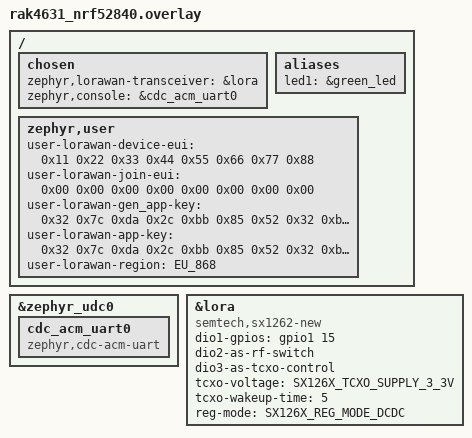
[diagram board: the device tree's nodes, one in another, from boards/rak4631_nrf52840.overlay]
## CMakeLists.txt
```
# SPDX-License-Identifier: Apache-2.0

cmake_minimum_required(VERSION 3.28.0)

find_package(Zephyr REQUIRED HINTS $ENV{ZEPHYR_BASE})
project(rzi_app)

target_sources(app PRIVATE src/main.c src/board.c)
target_link_libraries(app PRIVATE lbm_compile_definitions)
```

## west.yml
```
# 本文件是 west 清单（manifest）。west init / west update 只认根键 manifest:。
# 初始化：在工作区根 rzi/ 执行  west init -l app
#   -l = local，用本地这个 app/ 当老板仓，不去 GitHub 再 clone 一份清单仓。
# 不要给下面的 usp_zephyr 写 import: true，否则会并入它自带 west.yml 里锁死的 Zephyr v4.2.0。

# west 清单的唯一根键。self / remotes / projects 都必须缩进挂在它下面。
manifest:

  # 清单仓库自己（包含本 west.yml 的那个目录）。不是第三方，所以不进 projects，不会被 clone。
  self:
    # 老板仓相对工作区根的路径 → rzi/app。与 west init -l app、.west/config 里 path = app 一致。
    path: app

  # 远程 git 主机表。projects 里用 remote: 引用这里的 name，避免每个项目写完整 URL。
  remotes:
    # 列表第一项（- 表示一项）。名字 zephyrproject-rtos，下面 remote: zephyrproject-rtos 就是指它。
    - name: zephyrproject-rtos
      # URL 前缀。拼法：url-base + "/" + 项目 name → https://github.com/zephyrproject-rtos/zephyr
      url-base: https://github.com/zephyrproject-rtos
    # 第二个远程，给 Semtech 的 usp_zephyr 和 usp 用。
    - name: lora-net
      # LoRa-net 组织前缀。拼出 https://github.com/Lora-net/usp_zephyr 和 .../usp
      url-base: https://github.com/Lora-net

  # 要拉进工作区的第三方仓（不含 self）。west update 主要读这一块。
  projects:

    # 第一个项目。name 默认既是 GitHub 仓库名，也是本地目录名 → clone 到 rzi/zephyr/
    - name: zephyr
      # 用上面 remotes 里那个 zephyrproject-rtos → https://github.com/zephyrproject-rtos/zephyr
      remote: zephyrproject-rtos
      # 检出这一次 commit（当时的 Zephyr 4.4.99），不是浮动分支，也不是官方 USP 清单的 v4.2.0。
      revision: 161f758ba363ec90cd9b727a5d82e6c86efa85ad
      # 拉完后再读 zephyr/west.yml，把它列出的 HAL、mcuboot、tools 等并进本工作区。没有这行编 rak4631 会缺模块。
      import: true

    # 第二个项目。Semtech 的 Zephyr 封装（驱动、盾、sample、CMake）。clone 地址 = lora-net url-base + /usp_zephyr
    - name: usp_zephyr
      # → https://github.com/Lora-net/usp_zephyr
      remote: lora-net
      # 跟 main 分支最新提交。每次 west update 可能往前走；和上面 zephyr 钉 SHA 不同。
      revision: main
      # 放到工作区根下的 usp_zephyr/。这里 path 和 name 相同，不写也一样。
      # 注意：这一项没有 import: true，磁盘上的 usp_zephyr/west.yml west 不会读。
      # 本地改动用官方 west patch：app/zephyr/patches.yml，见 doc/west-patch.md。
      path: usp_zephyr

    # 第三个项目。协议栈本体（LBM + RAC），不是 usp_zephyr 那层封装。clone 地址 = https://github.com/Lora-net/usp
    - name: usp
      # 同样用 LoRa-net。
      remote: lora-net
      # 跟 usp 的 main，和 usp_zephyr 一样不锁死 SHA。
      revision: main
      # 本地必须放这里。这是 Zephyr/CMake 找 USP 模块的约定路径；放到别处构建系统找不到。
      path: modules/lib/usp
      # git clone / west update 时连该仓声明的 git submodule 一起拉（无线电驱动等）。不拉会缺源码。
      submodules: true
```

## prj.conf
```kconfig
# Own USP + LBM LoRaWAN app (not Zephyr CONFIG_LORAWAN / loramac-node).

# --- 板级外设 ---
CONFIG_BOARD_EARLY_INIT_HOOK=y         # app/src/board.c：全擦后把 REGOUT0 写成 3.3 V
CONFIG_GPIO=y                          # LED、SX1262 DIO / reset / busy
CONFIG_SPI=y                           # 和 SX1262 通信
CONFIG_SERIAL=y                        # UART 子系统（本板实际走 USB CDC）

# --- 控制台（overlay: zephyr,console = cdc_acm_uart0） ---
CONFIG_CONSOLE=y
CONFIG_UART_CONSOLE=y                  # printk / LOG 走 UART console
CONFIG_UART_LINE_CTRL=y                # CDC DTR；main.c wait_usb_console() 等主机打开串口
CONFIG_USE_SEGGER_RTT=n                # 关掉 RTT，日志不要跑到 J-Link

# --- USB CDC ACM：插 USB 当虚拟串口看 log ---
CONFIG_USB_DEVICE_STACK_NEXT=y         # 新 USB device 栈
CONFIG_CDC_ACM_SERIAL_INITIALIZE_AT_BOOT=y
CONFIG_CDC_ACM_SERIAL_PRODUCT_STRING="RAK4631 USP"
# 等 USB 枚举完再刷 log，避免开机丢字。数字赋值不要写同行注释。
CONFIG_LOG_PROCESS_THREAD_STARTUP_DELAY_MS=4000
CONFIG_USBD_CDC_ACM_LOG_LEVEL_OFF=y    # USB 栈自己的 log 关掉，枚举时不刷屏
CONFIG_USBD_LOG_LEVEL_OFF=y

# --- 日志与内存 ---
CONFIG_LOG=y
CONFIG_LOG_BACKEND_SHOW_COLOR=n        # CDC 不是彩色终端
CONFIG_LOG_BUFFER_SIZE=4096
CONFIG_HEAP_MEM_POOL_SIZE=8192
CONFIG_MAIN_STACK_SIZE=4096

# --- 存储 / 电源 / 随机数 ---
CONFIG_FLASH=y                         # LBM 把 Join 会话写 NVM
CONFIG_PM_DEVICE=y                     # 设备级电源管理（电台驱动会用）
CONFIG_TEST_RANDOM_GENERATOR=y         # 软件伪随机；Join DevNonce 等需要

# --- 关掉 Zephyr 自带 LoRa/LoRaWAN，避免和 USP 抢同一颗 SX1262 ---
CONFIG_LORA=n
CONFIG_LORAWAN=n

# --- USP + LoRa Basics Modem ---
CONFIG_LORA_BASICS_MODEM_DRIVERS=y     # SX1262 走 USP 驱动，不是树上 semtech,sx1262
CONFIG_LORA_BASICS_MODEM_DRIVERS_EVENT_TRIGGER_NO_THREAD=y  # DIO IRQ 不经中间线程，时间戳更准
CONFIG_USP=y
CONFIG_USP_LORA_BASICS_MODEM=y         # 编进 LBM 协议栈（join / MAC / 区域）
CONFIG_USP_MAIN_THREAD=y               # USP 自己跑 RAC 线程；main 只 init 然后 k_sleep

# --- 线程优先级（负数 = 协作式，不抢占；数字越小优先级越高） ---
# USP(-4) > main(-2)：main 让出 CPU 后 USP 立刻跑，临界区简单
CONFIG_MAIN_THREAD_PRIORITY=-2
CONFIG_USP_MAIN_THREAD_PRIORITY=-4
```

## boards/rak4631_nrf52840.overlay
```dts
/*
 * RAK4631：把板上 SX1262 交给 usp_zephyr，不要用树上的 Zephyr LoRa 驱动。
 *
 * 板级 dts 已有 &lora（SPI、reset、busy）和 aliases { lora0 }。
 * 树上 compatible 是 "semtech,sx1262"；本 overlay 改成 "semtech,sx1262-new"。
 *
 * 入网前改 zephyr,user 里的密钥。
 */

/* USP 头：SX126X_TCXO_SUPPLY_*、SX126X_REG_MODE_*。不是 Zephyr 自带的。 */
#include <zephyr/dt-bindings/usp/sx126x.h>

/ {
	chosen {
		/* USP：线程 / HAL 用 DT_CHOSEN(zephyr_lorawan_transceiver) 找电台 */
		zephyr,lorawan-transceiver = &lora;

		/* 日志走 USB CDC，与 USP 无关。板级默认是 uart1 */
		zephyr,console = &cdc_acm_uart0;
	};

	aliases {
		/* 板级只有 led0=蓝灯；绿灯给 main.c DT_ALIAS(led1) */
		led1 = &green_led;
	};

	/*
	 * 节点名 zephyr,user 是 Zephyr 通用的。
	 * 下面 user-lorawan-* 是 USP LBM sample / 本 app main.c 的约定。
	 */
	zephyr,user {
		/* ChirpStack 设备 RZI_001 */
		user-lorawan-device-eui = <0x11 0x22 0x33 0x44 0x55 0x66 0x77 0x88>;
		/* Configuration 页若不是全 0，改成和 Join EUI 一致 */
		user-lorawan-join-eui = <0x00 0x00 0x00 0x00 0x00 0x00 0x00 0x00>;
		/* Gen App Key（Remote Multicast）；LBM set_appkey */
		user-lorawan-gen_app-key = <0x32 0x7c 0xda 0x2c 0xbb 0x85 0x52 0x32
					    0xbe 0x7a 0x08 0xf5 0xc7 0x92 0xec 0x58>;
		/* OTAA AppKey；LoRaWAN 1.0 里 LBM set_nwkkey */
		user-lorawan-app-key = <0x32 0x7c 0xda 0x2c 0xbb 0x85 0x52 0x32
					0xbe 0x7a 0x08 0xf5 0xc7 0x92 0xec 0x58>;
		/* EU_868, CN_470, AS_923_GRP1, US_915, ... */
		user-lorawan-region = "EU_868";
	};
};

/* 普通 Zephyr USB CDC，与 USP 无关 */
&zephyr_udc0 {
	cdc_acm_uart0: cdc_acm_uart0 {
		compatible = "zephyr,cdc-acm-uart";
	};
};

/* USP 电台节点：binding 见 usp_zephyr/dts/bindings/usp/semtech,sx126x-new-common.yaml */
&lora {
	compatible = "semtech,sx1262-new";
	/* 脚位与板级 dts 相同；PULL_DOWN 给 USP 驱动 */
	dio1-gpios = <&gpio1 15 (GPIO_ACTIVE_HIGH | GPIO_PULL_DOWN)>;
	/* 以下属性只存在于 sx126x-new，树上旧驱动没有 */
	dio2-as-rf-switch;
	dio3-as-tcxo-control;
	/* 与 beegee SX126x-Arduino hw_config.TCXO_CTRL_VOLTAGE 默认值一致 */
	tcxo-voltage = <SX126X_TCXO_SUPPLY_3_3V>;
	tcxo-wakeup-time = <5>;
	reg-mode = <SX126X_REG_MODE_DCDC>;
	/* 删掉树上 semtech,sx1262 的旧属性，避免和新 binding 冲突 */
	/delete-property/ dio2-tx-enable;
	/delete-property/ dio3-tcxo-voltage;
	/delete-property/ tcxo-power-startup-delay-ms;
	/delete-property/ rx-enable-gpios;
};
```

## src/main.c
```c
/*
 * RAK4631 + usp_zephyr LoRaWAN example (app/, not usp_zephyr/samples).
 * OTAA join, then a 4-byte confirmed counter every 5 s on port 1.
 *
 * Fill DevEUI / JoinEUI / keys / region in boards/rak4631_nrf52840.overlay.
 */

#include <zephyr/kernel.h>
#include <zephyr/devicetree.h>
#include <zephyr/logging/log.h>
#include <zephyr/drivers/gpio.h>
#include <zephyr/drivers/uart.h>
#include <hal/nrf_power.h>

#include <smtc_modem_api.h>
#include <smtc_modem_utilities.h>
#include <smtc_zephyr_usp_api.h>
#include <smtc_sw_platform_helper.h>

LOG_MODULE_REGISTER(usp, LOG_LEVEL_INF);

#define STACK_ID 0
#define PERIOD_S 5
#define UPLINK_PORT 1

#define DT_MODEM_REGION(region) DT_CAT(SMTC_MODEM_REGION_, region)
#define MODEM_REGION DT_MODEM_REGION(DT_STRING_UNQUOTED(DT_PATH(zephyr_user), user_lorawan_region))

static const uint8_t user_dev_eui[8] = DT_PROP(DT_PATH(zephyr_user), user_lorawan_device_eui);
static const uint8_t user_join_eui[8] = DT_PROP(DT_PATH(zephyr_user), user_lorawan_join_eui);
static const uint8_t user_gen_app_key[16] = DT_PROP(DT_PATH(zephyr_user), user_lorawan_gen_app_key);
static const uint8_t user_app_key[16] = DT_PROP(DT_PATH(zephyr_user), user_lorawan_app_key);

static const struct gpio_dt_spec led_blue = GPIO_DT_SPEC_GET(DT_ALIAS(led0), gpios);
static const struct gpio_dt_spec led_green = GPIO_DT_SPEC_GET(DT_ALIAS(led1), gpios);

/* P1.05 = Arduino 37。Bernd：RADIO_RXEN + USE_RXEN_ANT_PWR = 天线开关的供电脚，
 * 不是通路选择脚。高电平有效，通电后方向由 SX1262 的 DIO2 自己切换，
 * 所以这里只需要常开、不需要每次 TX/RX 反复动作。 */
#define ANT_SWITCH_PWR_PIN 5
/* P1.07 原理图接到开关控制，官方要求不要初始化，交给 DIO2。 */
#define ANT_SWITCH_CTRL_PIN 7

static uint32_t uplink_counter;

static void led_set(const struct gpio_dt_spec *led, int value)
{
	if (gpio_is_ready_dt(led)) {
		gpio_pin_set_dt(led, value);
	}
}

static void led_green_blink_handler(struct k_timer *timer)
{
	ARG_UNUSED(timer);
	if (gpio_is_ready_dt(&led_green)) {
		gpio_pin_toggle_dt(&led_green);
	}
}

static void led_blue_off_work_handler(struct k_work *work)
{
	ARG_UNUSED(work);
	led_set(&led_blue, 0);
}

static K_TIMER_DEFINE(led_green_blink, led_green_blink_handler, NULL);
static K_WORK_DELAYABLE_DEFINE(led_blue_off_work, led_blue_off_work_handler);

static void led_blue_off(void)
{
	(void)k_work_cancel_delayable(&led_blue_off_work);
	led_set(&led_blue, 0);
}

/* 入网前绿灯闪；入网后绿灯常亮。蓝灯常灭，只在发送时快闪。 */
static void leds_joining(void)
{
	led_blue_off();
	led_set(&led_green, 1);
	k_timer_start(&led_green_blink, K_MSEC(500), K_MSEC(500));
}

static void leds_joined(void)
{
	k_timer_stop(&led_green_blink);
	led_set(&led_green, 1);
	led_blue_off();
}

/* 蓝灯常灭；每次上行快闪一下。关灯走 workqueue，避免 timer ISR 里 GPIO 没落下去。 */
static void led_blue_flash(void)
{
	led_set(&led_blue, 1);
	(void)k_work_reschedule(&led_blue_off_work, K_MSEC(80));
}

static int leds_init(void)
{
	if (!gpio_is_ready_dt(&led_blue) || !gpio_is_ready_dt(&led_green)) {
		LOG_ERR("LED gpio not ready");
		return -ENODEV;
	}

	gpio_pin_configure_dt(&led_blue, GPIO_OUTPUT_INACTIVE);
	gpio_pin_configure_dt(&led_green, GPIO_OUTPUT_INACTIVE);
	led_blue_off();
	return 0;
}

static void antenna_switch_power_on(void)
{
	const struct device *gpio1 = DEVICE_DT_GET(DT_NODELABEL(gpio1));
	int p105;

	if (!device_is_ready(gpio1)) {
		LOG_ERR("gpio1 not ready, P1.05 not driven");
		return;
	}

	/* 不要驱动 P1.07，避免和 SX1262 DIO2 抢开关。 */
	gpio_pin_configure(gpio1, ANT_SWITCH_CTRL_PIN, GPIO_INPUT);

	/*
	 * P1.05 是 RF 天线开关的供电（SX126x-Arduino USE_RXEN_ANT_PWR）。
	 * Bernd lora_rak4630_init：TX/RX 都 digitalWrite(37, HIGH)。
	 * 高电平才打开通路；板上 dts 的 GPIO_ACTIVE_LOW 是错的，别照抄。
	 */
	gpio_pin_configure(gpio1, ANT_SWITCH_PWR_PIN, GPIO_OUTPUT_HIGH);

	p105 = gpio_pin_get_raw(gpio1, ANT_SWITCH_PWR_PIN);
	LOG_INF("P1.05 raw=%d (expect 1) REGOUT0=0x%08x (3V3=5)", p105,
		(uint32_t)(NRF_UICR->REGOUT0 & UICR_REGOUT0_VOUT_Msk) >> UICR_REGOUT0_VOUT_Pos);
}

static void check_rc(const char *what, smtc_modem_return_code_t rc)
{
	if (rc != SMTC_MODEM_RC_OK) {
		LOG_ERR("%s failed: %d", what, rc);
	}
}

static void send_counter(void)
{
	uint8_t buff[4] = {
		(uplink_counter >> 24) & 0xFF,
		(uplink_counter >> 16) & 0xFF,
		(uplink_counter >> 8) & 0xFF,
		uplink_counter & 0xFF,
	};

	/* 天线开关供电是常开的（见 antenna_switch_power_on），这里不再重配
	 * 引脚：每次 uplink 前 gpio_pin_configure 会让脚短暂脱离输出态，
	 * 反而可能在 TX 瞬间把开关断电。 */
	smtc_modem_return_code_t rc =
		smtc_modem_request_uplink(STACK_ID, UPLINK_PORT, true, buff, sizeof(buff));
	if (rc != SMTC_MODEM_RC_OK) {
		LOG_ERR("uplink failed: %d", rc);
		return;
	}
	led_blue_flash();
	LOG_INF("confirmed uplink #%u on port %u", uplink_counter, UPLINK_PORT);
	uplink_counter++;
}

static void modem_event_callback(void)
{
	smtc_modem_event_t event = {0};
	uint8_t pending;

	do {
		check_rc("get_event", smtc_modem_get_event(&event, &pending));

		switch (event.event_type) {
		case SMTC_MODEM_EVENT_RESET:
			LOG_INF("RESET: set keys, region, join");
			leds_joining();
			check_rc("set_deveui", smtc_modem_set_deveui(STACK_ID, user_dev_eui));
			check_rc("set_joineui", smtc_modem_set_joineui(STACK_ID, user_join_eui));
			check_rc("set_appkey", smtc_modem_set_appkey(STACK_ID, user_gen_app_key));
			check_rc("set_nwkkey", smtc_modem_set_nwkkey(STACK_ID, user_app_key));
			check_rc("set_region", smtc_modem_set_region(STACK_ID, MODEM_REGION));
			/* 关掉 LoRaWAN Join 占空比退避（首小时约 toa/10，SF10 大约几十秒一次）。
			 * 调试用；量产应关掉，按规范退避。 */
			check_rc("join_dc_bypass",
				 smtc_modem_set_join_duty_cycle_backoff_bypass(STACK_ID, true));
			antenna_switch_power_on();
			check_rc("join", smtc_modem_join_network(STACK_ID));
			break;

		case SMTC_MODEM_EVENT_JOINED:
			LOG_INF("JOINED");
			leds_joined();
			send_counter();
			check_rc("alarm", smtc_modem_alarm_start_timer(PERIOD_S));
			break;

		case SMTC_MODEM_EVENT_JOINFAIL:
			LOG_WRN("JOINFAIL, retry in %u s", PERIOD_S);
			leds_joining();
			/* 取消 LBM 自己的 join 退避，改由 alarm 每 5 s 再 join */
			(void)smtc_modem_leave_network(STACK_ID);
			check_rc("alarm", smtc_modem_alarm_start_timer(PERIOD_S));
			break;

		case SMTC_MODEM_EVENT_ALARM: {
			smtc_modem_status_mask_t status = 0;

			check_rc("get_status", smtc_modem_get_status(STACK_ID, &status));
			if ((status & SMTC_MODEM_STATUS_JOINED) != 0) {
				send_counter();
				check_rc("alarm", smtc_modem_alarm_start_timer(PERIOD_S));
			} else {
				LOG_INF("join retry");
				check_rc("join", smtc_modem_join_network(STACK_ID));
			}
			break;
		}

		case SMTC_MODEM_EVENT_TXDONE: {
			smtc_modem_event_txdone_status_t st = event.event_data.txdone.status;

			if (st == SMTC_MODEM_EVENT_TXDONE_CONFIRMED) {
				LOG_INF("TXDONE ACK");
			} else if (st == SMTC_MODEM_EVENT_TXDONE_SENT) {
				LOG_WRN("TXDONE sent, no ACK");
			} else {
				LOG_WRN("TXDONE not sent (%d)", st);
			}
			led_blue_off();
			break;
		}

		case SMTC_MODEM_EVENT_DOWNDATA: {
			uint8_t payload[SMTC_MODEM_MAX_LORAWAN_PAYLOAD_LENGTH];
			uint8_t size = 0;
			uint8_t remaining = 0;
			smtc_modem_dl_metadata_t meta = {0};

			check_rc("downlink",
				 smtc_modem_get_downlink_data(payload, &size, &meta, &remaining));
			LOG_INF("DOWNLINK port %u, %u bytes", meta.fport, size);
			break;
		}

		default:
			LOG_DBG("event %u", event.event_type);
			break;
		}
	} while (pending > 0);
}

static void wait_usb_console(void)
{
	const struct device *dev = DEVICE_DT_GET(DT_CHOSEN(zephyr_console));
	uint32_t dtr = 0;
	int64_t deadline = k_uptime_get() + 10000;

	if (!device_is_ready(dev)) {
		return;
	}

	while (dtr == 0 && k_uptime_get() < deadline) {
		(void)uart_line_ctrl_get(dev, UART_LINE_CTRL_DTR, &dtr);
		k_sleep(K_MSEC(100));
	}
}

int main(void)
{
	(void)leds_init();
	leds_joining();

	wait_usb_console();

	LOG_INF("rzi USP LoRaWAN on %s", CONFIG_BOARD_TARGET);
	LOG_INF("DevEUI %02X%02X%02X%02X%02X%02X%02X%02X", user_dev_eui[0], user_dev_eui[1],
		user_dev_eui[2], user_dev_eui[3], user_dev_eui[4], user_dev_eui[5], user_dev_eui[6],
		user_dev_eui[7]);

	antenna_switch_power_on();

	SMTC_SW_PLATFORM_INIT();
	SMTC_SW_PLATFORM_VOID(smtc_rac_init());
	SMTC_SW_PLATFORM_VOID(smtc_modem_init(&modem_event_callback));

	LOG_INF("joining (edit keys in boards/rak4631_nrf52840.overlay)");

	k_sleep(K_FOREVER);
	return 0;
}
```

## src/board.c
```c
/*
 * RAK4631: nRF52840 runs from VDDH. After a full erase, UICR REGOUT0
 * defaults to 1.8 V. LEDs/USB may still work, but SX1262 GPIOs do not.
 * Write REGOUT0 to 3.3 V and reset so the new GPIO voltage takes effect.
 *
 * Official rak4631 board has no board.c; keep this in the app so west
 * update does not wipe it.
 */

#include <zephyr/init.h>
#include <hal/nrf_power.h>

void board_early_init_hook(void)
{
	if ((nrf_power_mainregstatus_get(NRF_POWER) == NRF_POWER_MAINREGSTATUS_HIGH) &&
	    ((NRF_UICR->REGOUT0 & UICR_REGOUT0_VOUT_Msk) ==
	     (UICR_REGOUT0_VOUT_DEFAULT << UICR_REGOUT0_VOUT_Pos))) {

		NRF_NVMC->CONFIG = NVMC_CONFIG_WEN_Wen << NVMC_CONFIG_WEN_Pos;
		while (NRF_NVMC->READY == NVMC_READY_READY_Busy) {
			;
		}

		NRF_UICR->REGOUT0 =
			(NRF_UICR->REGOUT0 & ~((uint32_t)UICR_REGOUT0_VOUT_Msk)) |
			(UICR_REGOUT0_VOUT_3V3 << UICR_REGOUT0_VOUT_Pos);

		NRF_NVMC->CONFIG = NVMC_CONFIG_WEN_Ren << NVMC_CONFIG_WEN_Pos;
		while (NRF_NVMC->READY == NVMC_READY_READY_Busy) {
			;
		}

		/* UICR writes take effect only after reset. */
		NVIC_SystemReset();
	}
}
```
